# trng_revb2 register map
Registers are access not given, no defined reset value unless marked. A register's access mark holds for its fields unless they carry their own. Offsets are from the block's base; lines under a group give offsets from that group; [hi:lo] are bit positions; {n}, {i} and the like mark numbered series; 'fields as' and 'values as' point back to an identical list; <NAME> marks a mode.

## Memory map
0x4004D000 TRNG size 0x1000 — Random Number Generator.

## Interrupts
4 TRNG — TRNG interrupt.

## TRNG — Random Number Generator.
Base 0x4004D000
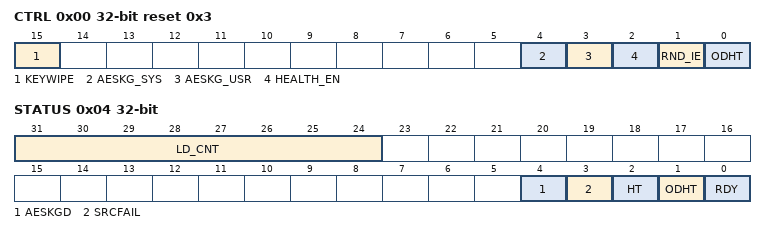
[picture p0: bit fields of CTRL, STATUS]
0x00 CTRL reset 0x3 — TRNG Control Register.
  [15] KEYWIPE — To wipe the Battery Backed key.
  [4] AESKG_SYS
  [3] AESKG_USR — AES Key Generate. When enabled, the key for securing NVSRAM is generated and transferred to the secure key register automatically without user visibility or intervention. This bit is cleared by hardware once the key has been transferred to the secure key register.
  [2] HEALTH_EN — Enable IRQ generation when a health test fails.
  [1] RND_IE — To enable IRQ generation when a new 32-bit Random number is ready.
    0=disable; 1=enable
  [0] ODHT — Start On-Demand health test.
0x04 STATUS — Data. The content of this register is valid only when RNG_IS = 1. When TRNG is disabled, read returns 0x0000 0000.
  [31:24] LD_CNT
  [4] AESKGD
  [3] SRCFAIL — Entropy source has failed.
  [2] HT — Health test status.
  [1] ODHT — On-Demand health test status.
  [0] RDY — 32-bit random data is ready to read from TRNG_DATA register. Reading TRNG_DATA when RND_RDY=0 will return all 0's. IRQ is generated when RND_RDY=1 if TRNG_CN.RND_IRQ_EN=1.
    0=Busy (TRNG Busy); 1=Ready (32 bit random data is ready)
0x08 DATA ro — Data. The content of this register is valid only when RNG_IS = 1. When TRNG is disabled, read returns 0x0000 0000.
  [31:0] DATA — Data. The content of this register is valid only when RNG_IS =1. When TNRG is disabled, read returns 0x0000 0000.
